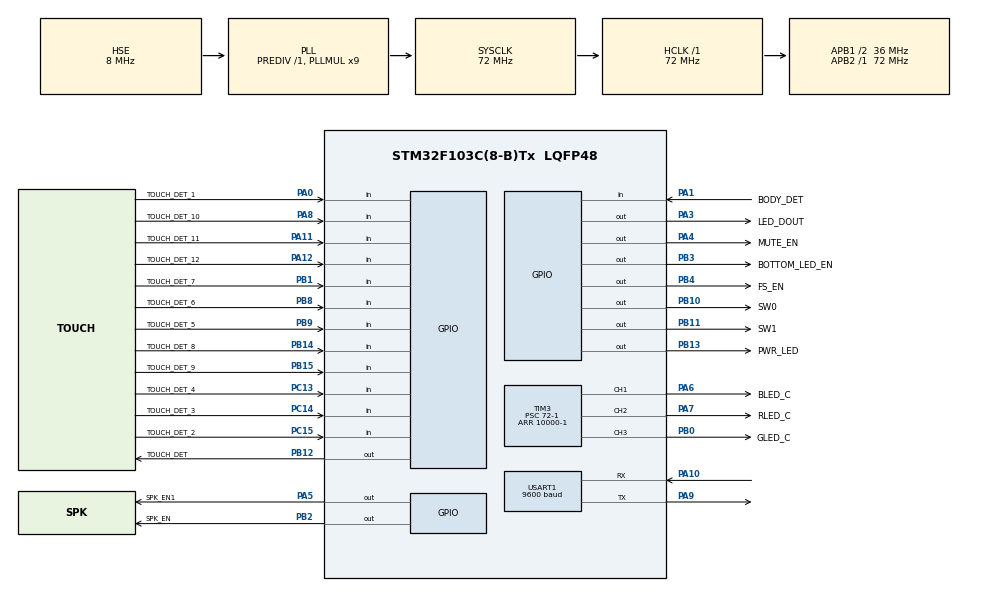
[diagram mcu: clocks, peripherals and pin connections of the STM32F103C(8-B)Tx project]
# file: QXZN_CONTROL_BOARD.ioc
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Mcu.Family=STM32F1
Mcu.Name=STM32F103C(8-B)Tx
Mcu.Package=LQFP48
NVIC.PriorityGroup=NVIC_PRIORITYGROUP_2
NVIC.TIM4_IRQn=true\:1\:1\:true\:false\:true\:true
NVIC.USART1_IRQn=true\:0\:0\:false\:false\:true\:true
PA0-WKUP.GPIO_Label=TOUCH_DET_1
PA0-WKUP.Signal=GPIO_Input
PA1.GPIO_Label=BODY_DET
PA1.Signal=GPIO_Input
PA10.Mode=Asynchronous
PA10.Signal=USART1_RX
PA11.GPIO_Label=TOUCH_DET_11
PA11.Signal=GPIO_Input
PA12.GPIO_Label=TOUCH_DET_12
PA12.Signal=GPIO_Input
PA13.Mode=Serial_Wire
PA13.Signal=SYS_JTMS-SWDIO
PA14.Mode=Serial_Wire
PA14.Signal=SYS_JTCK-SWCLK
PA3.GPIO_Label=LED_DOUT
PA3.Signal=GPIO_Output
PA4.GPIO_Label=MUTE_EN
PA4.Signal=GPIO_Output
PA5.GPIO_Label=SPK_EN1
PA5.Signal=GPIO_Output
PA6.GPIO_Label=BLED_C
PA6.Signal=S_TIM3_CH1
PA7.GPIO_Label=RLED_C
PA7.Signal=S_TIM3_CH2
PA8.GPIO_Label=TOUCH_DET_10
PA8.Signal=GPIO_Input
PA9.Mode=Asynchronous
PA9.Signal=USART1_TX
PB0.GPIO_Label=GLED_C
PB0.Signal=S_TIM3_CH3
PB1.GPIO_Label=TOUCH_DET_7
PB1.Signal=GPIO_Input
PB10.GPIO_Label=SW0
PB10.Signal=GPIO_Output
PB11.GPIO_Label=SW1
PB11.Signal=GPIO_Output
PB12.GPIO_Label=TOUCH_DET
PB12.Signal=GPIO_Output
PB13.GPIO_Label=PWR_LED
PB13.Signal=GPIO_Output
PB14.GPIO_Label=TOUCH_DET_8
PB14.Signal=GPIO_Input
PB15.GPIO_Label=TOUCH_DET_9
PB15.Signal=GPIO_Input
PB2.GPIO_Label=SPK_EN
PB2.Signal=GPIO_Output
PB3.GPIO_Label=BOTTOM_LED_EN
PB3.Signal=GPIO_Output
PB4.GPIO_Label=FS_EN
PB4.Signal=GPIO_Output
PB8.GPIO_Label=TOUCH_DET_6
PB8.Signal=GPIO_Input
PB9.GPIO_Label=TOUCH_DET_5
PB9.Signal=GPIO_Input
PC13-TAMPER-RTC.GPIO_Label=TOUCH_DET_4
PC13-TAMPER-RTC.Signal=GPIO_Input
PC14-OSC32_IN.GPIO_Label=TOUCH_DET_3
PC14-OSC32_IN.Signal=GPIO_Input
PC15-OSC32_OUT.GPIO_Label=TOUCH_DET_2
PC15-OSC32_OUT.Signal=GPIO_Input
PD0-OSC_IN.Mode=HSE-External-Oscillator
PD0-OSC_IN.Signal=RCC_OSC_IN
PD1-OSC_OUT.Mode=HSE-External-Oscillator
PD1-OSC_OUT.Signal=RCC_OSC_OUT
ProjectManager.HeapSize=0x200
ProjectManager.StackSize=0x400
ProjectManager.TargetToolchain=MDK-ARM V5
RCC.AHBFreq_Value=72000000
RCC.APB1CLKDivider=RCC_HCLK_DIV2
RCC.APB1Freq_Value=36000000
RCC.APB1TimFreq_Value=72000000
RCC.APB2Freq_Value=72000000
RCC.APB2TimFreq_Value=72000000
RCC.HCLKFreq_Value=72000000
RCC.PLLMUL=RCC_PLL_MUL9
RCC.PLLSourceVirtual=RCC_PLLSOURCE_HSE
RCC.SYSCLKFreq_VALUE=72000000
RCC.SYSCLKSource=RCC_SYSCLKSOURCE_PLLCLK
RCC.USBFreq_Value=72000000
SH.S_TIM3_CH1.0=TIM3_CH1,PWM Generation1 CH1
SH.S_TIM3_CH2.0=TIM3_CH2,PWM Generation2 CH2
SH.S_TIM3_CH3.0=TIM3_CH3,PWM Generation3 CH3
TIM3.AutoReloadPreload=TIM_AUTORELOAD_PRELOAD_ENABLE
TIM3.Channel-PWM\ Generation1\ CH1=TIM_CHANNEL_1
TIM3.Channel-PWM\ Generation2\ CH2=TIM_CHANNEL_2
TIM3.Channel-PWM\ Generation3\ CH3=TIM_CHANNEL_3
TIM3.Period=10000-1
TIM3.Prescaler=72-1
TIM3.Pulse-PWM\ Generation1\ CH1=1000-1
TIM3.Pulse-PWM\ Generation2\ CH2=1000-1
TIM3.Pulse-PWM\ Generation3\ CH3=1000-1
TIM4.AutoReloadPreload=TIM_AUTORELOAD_PRELOAD_ENABLE
TIM4.Period=100-1
TIM4.Prescaler=720-1
USART1.BaudRate=9600
USART1.VirtualMode=VM_ASYNC
VP_TIM4_VS_ClockSourceINT.Mode=Internal
board=QXZN_CONTROL_BOARD

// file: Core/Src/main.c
/**
  ******************************************************************************
  * @file           : main.c
  * @brief          : Main program body
  ******************************************************************************
  ** This notice applies to any and all portions of this file
  * that are not between comment pairs USER CODE BEGIN and
  * USER CODE END. Other portions of this file, whether
  * inserted by the user or by software development tools
  * are owned by their respective copyright owners.
  *
  * COPYRIGHT(c) 2018 STMicroelectronics
  *
  * Redistribution and use in source and binary forms, with or without modification,
  * are permitted provided that the following conditions are met:
  *   1. Redistributions of source code must retain the above copyright notice,
  *      this list of conditions and the following disclaimer.
  *   2. Redistributions in binary form must reproduce the above copyright notice,
  *      this list of conditions and the following disclaimer in the documentation
  *      and/or other materials provided with the distribution.
  *   3. Neither the name of STMicroelectronics nor the names of its contributors
  *      may be used to endorse or promote products derived from this software
  *      without specific prior written permission.
  *
  * THIS SOFTWARE IS PROVIDED BY THE COPYRIGHT HOLDERS AND CONTRIBUTORS "AS IS"
  * AND ANY EXPRESS OR IMPLIED WARRANTIES, INCLUDING, BUT NOT LIMITED TO, THE
  * IMPLIED WARRANTIES OF MERCHANTABILITY AND FITNESS FOR A PARTICULAR PURPOSE ARE
  * DISCLAIMED. IN NO EVENT SHALL THE COPYRIGHT HOLDER OR CONTRIBUTORS BE LIABLE
  * FOR ANY DIRECT, INDIRECT, INCIDENTAL, SPECIAL, EXEMPLARY, OR CONSEQUENTIAL
  * DAMAGES (INCLUDING, BUT NOT LIMITED TO, PROCUREMENT OF SUBSTITUTE GOODS OR
  * SERVICES; LOSS OF USE, DATA, OR PROFITS; OR BUSINESS INTERRUPTION) HOWEVER
  * CAUSED AND ON ANY THEORY OF LIABILITY, WHETHER IN CONTRACT, STRICT LIABILITY,
  * OR TORT (INCLUDING NEGLIGENCE OR OTHERWISE) ARISING IN ANY WAY OUT OF THE USE
  * OF THIS SOFTWARE, EVEN IF ADVISED OF THE POSSIBILITY OF SUCH DAMAGE.
  *
  ******************************************************************************
  */
#include "main.h"
#include "stm32f1xx_hal.h"
#include "tim.h"
#include "usart.h"
#include "gpio.h"

/* USER CODE BEGIN Includes */
#include "user.h"
#include "ws2813b.h"
/* USER CODE END Includes */

/* USER CODE BEGIN PV */
/* Private variables ---------------------------------------------------------*/

/* USER CODE END PV */

void SystemClock_Config(void);

/* USER CODE BEGIN PFP */
/* Private function prototypes -----------------------------------------------*/

/* USER CODE END PFP */

/* USER CODE BEGIN 0 */
//uint8_t STOP = 1;
//uint8_t aTxStartMessage[] = "\r\n****UART-Hyperterminal communication based on IT ****\r\nEnter 10 characters using keyboard :\r";

/* USER CODE END 0 */

int main(void)
{

  /* MCU Configuration----------------------------------------------------------*/

  /* Reset of all peripherals, Initializes the Flash interface and the Systick. */
  HAL_Init();

  /* Configure the system clock */
  SystemClock_Config();

  /* Initialize all configured peripherals */
  MX_GPIO_Init();
  MX_USART1_UART_Init();
  MX_TIM3_Init();
  MX_TIM4_Init();
  /* USER CODE BEGIN 2 */
	user_board_init();
  /* USER CODE END 2 */

  /* Infinite loop */
  while (1)
  {

  /* USER CODE BEGIN 3 */
		user_progress();
	}
  /* USER CODE END 3 */

}

void SystemClock_Config(void)
{

  RCC_OscInitTypeDef RCC_OscInitStruct;
  RCC_ClkInitTypeDef RCC_ClkInitStruct;

    /**Initializes the CPU, AHB and APB busses clocks
    */
  RCC_OscInitStruct.OscillatorType = RCC_OSCILLATORTYPE_HSE;
  RCC_OscInitStruct.HSEState = RCC_HSE_ON;
  RCC_OscInitStruct.HSEPredivValue = RCC_HSE_PREDIV_DIV1;
  RCC_OscInitStruct.HSIState = RCC_HSI_ON;
  RCC_OscInitStruct.PLL.PLLState = RCC_PLL_ON;
  RCC_OscInitStruct.PLL.PLLSource = RCC_PLLSOURCE_HSE;
  RCC_OscInitStruct.PLL.PLLMUL = RCC_PLL_MUL9;
  if (HAL_RCC_OscConfig(&RCC_OscInitStruct) != HAL_OK)
  {
    _Error_Handler(__FILE__, __LINE__);
  }

    /**Initializes the CPU, AHB and APB busses clocks
    */
  RCC_ClkInitStruct.ClockType = RCC_CLOCKTYPE_HCLK|RCC_CLOCKTYPE_SYSCLK
                              |RCC_CLOCKTYPE_PCLK1|RCC_CLOCKTYPE_PCLK2;
  RCC_ClkInitStruct.SYSCLKSource = RCC_SYSCLKSOURCE_PLLCLK;
  RCC_ClkInitStruct.AHBCLKDivider = RCC_SYSCLK_DIV1;
  RCC_ClkInitStruct.APB1CLKDivider = RCC_HCLK_DIV2;
  RCC_ClkInitStruct.APB2CLKDivider = RCC_HCLK_DIV1;

  if (HAL_RCC_ClockConfig(&RCC_ClkInitStruct, FLASH_LATENCY_2) != HAL_OK)
  {
    _Error_Handler(__FILE__, __LINE__);
  }

    /**Configure the Systick interrupt time
    */
  HAL_SYSTICK_Config(HAL_RCC_GetHCLKFreq()/1000);

    /**Configure the Systick
    */
  HAL_SYSTICK_CLKSourceConfig(SYSTICK_CLKSOURCE_HCLK);

  /* SysTick_IRQn interrupt configuration */
  HAL_NVIC_SetPriority(SysTick_IRQn, 0, 0);
}

void _Error_Handler(char *file, int line)
{
  while(1)
  {
  }
}

/************************ (C) COPYRIGHT STMicroelectronics *****END OF FILE****/
